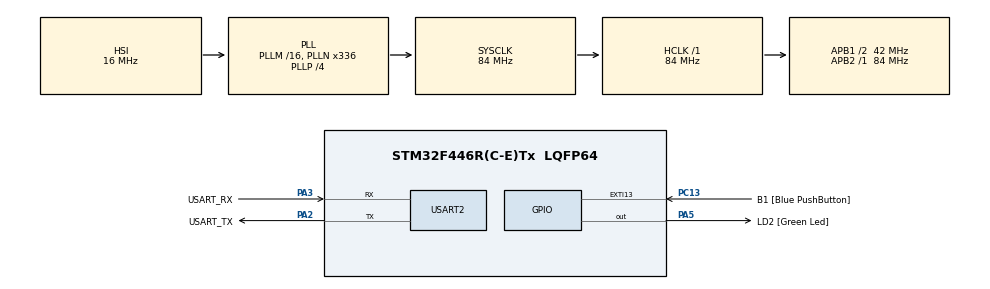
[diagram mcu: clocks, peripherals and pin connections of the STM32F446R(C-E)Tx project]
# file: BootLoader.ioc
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Mcu.Family=STM32F4
Mcu.Name=STM32F446R(C-E)Tx
Mcu.Package=LQFP64
NVIC.PriorityGroup=NVIC_PRIORITYGROUP_0
PA13.GPIO_Label=TMS
PA13.Mode=Serial_Wire
PA13.Signal=SYS_JTMS-SWDIO
PA14.GPIO_Label=TCK
PA14.Mode=Serial_Wire
PA14.Signal=SYS_JTCK-SWCLK
PA2.GPIO_Label=USART_TX
PA2.Mode=Asynchronous
PA2.Signal=USART2_TX
PA3.GPIO_Label=USART_RX
PA3.Mode=Asynchronous
PA3.Signal=USART2_RX
PA5.GPIO_Label=LD2 [Green Led]
PA5.Signal=GPIO_Output
PB3.GPIO_Label=SWO
PB3.Signal=SYS_JTDO-SWO
PC13.GPIO_Label=B1 [Blue PushButton]
PC13.GPIO_ModeDefaultEXTI=GPIO_MODE_IT_FALLING
PC13.Signal=GPXTI13
PC14-OSC32_IN.Mode=LSE-External-Oscillator
PC14-OSC32_IN.Signal=RCC_OSC32_IN
PC15-OSC32_OUT.Mode=LSE-External-Oscillator
PC15-OSC32_OUT.Signal=RCC_OSC32_OUT
PH0-OSC_IN.Mode=HSE-External-Oscillator
PH0-OSC_IN.Signal=RCC_OSC_IN
PH1-OSC_OUT.Mode=HSE-External-Oscillator
PH1-OSC_OUT.Signal=RCC_OSC_OUT
ProjectManager.HeapSize=0x200
ProjectManager.StackSize=0x400
ProjectManager.TargetToolchain=STM32CubeIDE
RCC.48MHZClocksFreq_Value=84000000
RCC.AHBFreq_Value=84000000
RCC.APB1CLKDivider=RCC_HCLK_DIV2
RCC.APB1Freq_Value=42000000
RCC.APB1TimFreq_Value=84000000
RCC.APB2Freq_Value=84000000
RCC.APB2TimFreq_Value=84000000
RCC.CortexFreq_Value=84000000
RCC.FLatency-AdvancedSettings=FLASH_LATENCY_2
RCC.HCLKFreq_Value=84000000
RCC.HSE_VALUE=8000000
RCC.HSI_VALUE=16000000
RCC.PLLN=336
RCC.PLLP=RCC_PLLP_DIV4
RCC.SYSCLKFreq_VALUE=84000000
RCC.SYSCLKSource=RCC_SYSCLKSOURCE_PLLCLK
RCC.USBFreq_Value=168000000
RCC.VCOOutputFreq_Value=336000000
USART2.VirtualMode=VM_ASYNC
board=NUCLEO-F446RE

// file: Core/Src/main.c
/* USER CODE BEGIN Header */
/**
 ******************************************************************************
 * @file           : main.c
 * @brief          : Simple Bootloader example
 ******************************************************************************
 */
/* USER CODE END Header */
#include "main.h"

/* USER CODE BEGIN Includes */
#include "general.h"
#include "stdbool.h"
/* USER CODE END Includes */

UART_HandleTypeDef huart2;

void SystemClock_Config(void);
static void MX_GPIO_Init(void);
static void MX_USART2_UART_Init(void);

/* USER CODE BEGIN 0 */
typedef void (*pFunction)(void);
void goto_APP(void);
pFunction JumpToApplication;
uint32_t JumpAddress;

#define APP_ADD     0x08008000
#define APP_ADDRESS 0x08008000
#define FLASH_PAGE_SIZE 0x4000  // 16 KB typical for STM32F4
#define MAX_APP_SIZE 0x60000    // Example max size (384 KB)

uint8_t rx_buffer[256];

/* USER CODE END 0 */

int main(void)
{

  HAL_Init();
  SystemClock_Config();
  MX_GPIO_Init();
  MX_USART2_UART_Init();

  /* USER CODE BEGIN 2 */

  receive_and_flash();

  goto_APP();

  /* USER CODE END 2 */

  while (1)
  {
    /* USER CODE BEGIN 3 */
    // Optional: put error handling or standby here
    /* USER CODE END 3 */
  }
}

void SystemClock_Config(void) {
	RCC_OscInitTypeDef RCC_OscInitStruct = { 0 };
	RCC_ClkInitTypeDef RCC_ClkInitStruct = { 0 };

	/** Configure the main internal regulator output voltage
	 */
	__HAL_RCC_PWR_CLK_ENABLE();
	__HAL_PWR_VOLTAGESCALING_CONFIG(PWR_REGULATOR_VOLTAGE_SCALE3);

	/** Initializes the RCC Oscillators according to the specified parameters
	 * in the RCC_OscInitTypeDef structure.
	 */
	RCC_OscInitStruct.OscillatorType = RCC_OSCILLATORTYPE_HSI;
	RCC_OscInitStruct.HSIState = RCC_HSI_ON;
	RCC_OscInitStruct.HSICalibrationValue = RCC_HSICALIBRATION_DEFAULT;
	RCC_OscInitStruct.PLL.PLLState = RCC_PLL_ON;
	RCC_OscInitStruct.PLL.PLLSource = RCC_PLLSOURCE_HSI;
	RCC_OscInitStruct.PLL.PLLM = 16;
	RCC_OscInitStruct.PLL.PLLN = 336;
	RCC_OscInitStruct.PLL.PLLP = RCC_PLLP_DIV4;
	RCC_OscInitStruct.PLL.PLLQ = 2;
	RCC_OscInitStruct.PLL.PLLR = 2;
	if (HAL_RCC_OscConfig(&RCC_OscInitStruct) != HAL_OK) {
		Error_Handler();
	}

	/** Initializes the CPU, AHB and APB buses clocks
	 */
	RCC_ClkInitStruct.ClockType = RCC_CLOCKTYPE_HCLK | RCC_CLOCKTYPE_SYSCLK
			| RCC_CLOCKTYPE_PCLK1 | RCC_CLOCKTYPE_PCLK2;
	RCC_ClkInitStruct.SYSCLKSource = RCC_SYSCLKSOURCE_PLLCLK;
	RCC_ClkInitStruct.AHBCLKDivider = RCC_SYSCLK_DIV1;
	RCC_ClkInitStruct.APB1CLKDivider = RCC_HCLK_DIV2;
	RCC_ClkInitStruct.APB2CLKDivider = RCC_HCLK_DIV1;

	if (HAL_RCC_ClockConfig(&RCC_ClkInitStruct, FLASH_LATENCY_2) != HAL_OK) {
		Error_Handler();
	}
}

static void MX_USART2_UART_Init(void) {

	huart2.Instance = USART2;
	huart2.Init.BaudRate = 115200;
	huart2.Init.WordLength = UART_WORDLENGTH_8B;
	huart2.Init.StopBits = UART_STOPBITS_1;
	huart2.Init.Parity = UART_PARITY_NONE;
	huart2.Init.Mode = UART_MODE_TX_RX;
	huart2.Init.HwFlowCtl = UART_HWCONTROL_NONE;
	huart2.Init.OverSampling = UART_OVERSAMPLING_16;
	if (HAL_UART_Init(&huart2) != HAL_OK) {
		Error_Handler();
	}

}

static void MX_GPIO_Init(void) {
	GPIO_InitTypeDef GPIO_InitStruct = { 0 };

	/* GPIO Ports Clock Enable */
	__HAL_RCC_GPIOC_CLK_ENABLE();
	__HAL_RCC_GPIOH_CLK_ENABLE();
	__HAL_RCC_GPIOA_CLK_ENABLE();
	__HAL_RCC_GPIOB_CLK_ENABLE();

	/*Configure GPIO pin Output Level */
	HAL_GPIO_WritePin(LD2_GPIO_Port, LD2_Pin, GPIO_PIN_RESET);

	/*Configure GPIO pin : B1_Pin */
	GPIO_InitStruct.Pin = B1_Pin;
	GPIO_InitStruct.Mode = GPIO_MODE_IT_FALLING;
	GPIO_InitStruct.Pull = GPIO_NOPULL;
	HAL_GPIO_Init(B1_GPIO_Port, &GPIO_InitStruct);

	/*Configure GPIO pin : LD2_Pin */
	GPIO_InitStruct.Pin = LD2_Pin;
	GPIO_InitStruct.Mode = GPIO_MODE_OUTPUT_PP;
	GPIO_InitStruct.Pull = GPIO_NOPULL;
	GPIO_InitStruct.Speed = GPIO_SPEED_FREQ_LOW;
	HAL_GPIO_Init(LD2_GPIO_Port, &GPIO_InitStruct);

	/* USART1 RX (PB7) */
	GPIO_InitStruct.Pin = GPIO_PIN_7;
	GPIO_InitStruct.Mode = GPIO_MODE_AF_PP;
	GPIO_InitStruct.Pull = GPIO_NOPULL;
	GPIO_InitStruct.Speed = GPIO_SPEED_FREQ_VERY_HIGH;
	GPIO_InitStruct.Alternate = GPIO_AF7_USART1;
	HAL_GPIO_Init(GPIOB, &GPIO_InitStruct);
}

/* USER CODE BEGIN 4 */
void goto_APP(void) {
    printf("Bootloader: jumping to app\n");

    // Disable interrupt sources
    HAL_NVIC_DisableIRQ(USART2_IRQn);
    HAL_NVIC_DisableIRQ(EXTI15_10_IRQn);

    // De-init peripherals
    HAL_UART_DeInit(&huart2);
    HAL_RCC_DeInit();

    // Optionally reset GPIOs
    HAL_GPIO_DeInit(GPIOA, GPIO_PIN_All);
    HAL_GPIO_DeInit(GPIOB, GPIO_PIN_All);

    // Set vector table offset (optional)
    SCB->VTOR = APP_ADD;

    // Set MSP
    __set_MSP(*(__IO uint32_t*)APP_ADD);

    // Get reset handler address
    JumpAddress = *(__IO uint32_t*) (APP_ADD + 4);
    JumpToApplication = (pFunction)JumpAddress;

    // Jump
    JumpToApplication();
}

#define EXPECTED_SIZE 100000  // total bytes expected

void receive_and_flash(void)
{
    HAL_StatusTypeDef status;

    // ================================
    // >>> Configure USART1 GPIO pins
    // ================================
    GPIO_InitTypeDef GPIO_InitStruct = {0};

    __HAL_RCC_GPIOB_CLK_ENABLE();
    __HAL_RCC_USART1_CLK_ENABLE();

    // PB6 = USART1_TX
    GPIO_InitStruct.Pin = GPIO_PIN_6;
    GPIO_InitStruct.Mode = GPIO_MODE_AF_PP;
    GPIO_InitStruct.Pull = GPIO_NOPULL;
    GPIO_InitStruct.Speed = GPIO_SPEED_FREQ_VERY_HIGH;
    GPIO_InitStruct.Alternate = GPIO_AF7_USART1;
    HAL_GPIO_Init(GPIOB, &GPIO_InitStruct);

    // PB7 = USART1_RX
    GPIO_InitStruct.Pin = GPIO_PIN_7;
    GPIO_InitStruct.Mode = GPIO_MODE_AF_PP;
    GPIO_InitStruct.Pull = GPIO_NOPULL;
    GPIO_InitStruct.Speed = GPIO_SPEED_FREQ_VERY_HIGH;
    GPIO_InitStruct.Alternate = GPIO_AF7_USART1;
    HAL_GPIO_Init(GPIOB, &GPIO_InitStruct);

    // ===========================
    // >>> Init USART1
    // ===========================
    UART_HandleTypeDef huart1;
    huart1.Instance = USART1;
    huart1.Init.BaudRate = 115200;
    huart1.Init.WordLength = UART_WORDLENGTH_8B;
    huart1.Init.StopBits = UART_STOPBITS_1;
    huart1.Init.Parity = UART_PARITY_NONE;
    huart1.Init.Mode = UART_MODE_TX_RX;
    huart1.Init.HwFlowCtl = UART_HWCONTROL_NONE;
    huart1.Init.OverSampling = UART_OVERSAMPLING_16;
    if (HAL_UART_Init(&huart1) != HAL_OK)
    {
        Error_Handler();
    }

    // Buffer to accumulate received data
    uint8_t *rx_buffer = malloc(EXPECTED_SIZE);
    if (!rx_buffer) {
        // Allocation failed
        Error_Handler();
    }

    uint32_t receivedSize = 0;
    uint32_t startTick = HAL_GetTick();
    const uint32_t timeoutMs = 10000; // 10 seconds overall timeout

    while ((HAL_GetTick() - startTick) < timeoutMs && receivedSize < EXPECTED_SIZE)
    {
        // Receive in small chunks (e.g. 64 bytes) to avoid big blocking
        uint32_t chunkSize = 64;
        if ((EXPECTED_SIZE - receivedSize) < chunkSize) {
            chunkSize = EXPECTED_SIZE - receivedSize;
        }

        status = HAL_UART_Receive(&huart1, rx_buffer + receivedSize, chunkSize, 500);

        if (status == HAL_OK)
        {
            receivedSize += chunkSize;
            startTick = HAL_GetTick();  // reset timeout on receive
        }
        else if (status == HAL_TIMEOUT)
        {
            // no data for 500ms chunk, continue to wait if total time not exceeded
            continue;
        }
        else
        {
            // other errors, break early
            break;
        }
    }

    if (receivedSize > 1000 )
    {
        // We have full data - flash it!

        HAL_FLASH_Unlock();

        FLASH_EraseInitTypeDef EraseInitStruct;
        uint32_t SectorError = 0;
        EraseInitStruct.TypeErase = FLASH_TYPEERASE_SECTORS;
        EraseInitStruct.VoltageRange = FLASH_VOLTAGE_RANGE_3;
        EraseInitStruct.Sector = FLASH_SECTOR_2;
        EraseInitStruct.NbSectors = 6;
        if (HAL_FLASHEx_Erase(&EraseInitStruct, &SectorError) != HAL_OK)
        {
            free(rx_buffer);
            Error_Handler();
        }

        uint32_t appAddress = APP_ADD;

        // Flash in 4-byte words
        for (uint32_t i = 0; i < receivedSize; i += 4)
        {
            uint32_t word = *(uint32_t *)(rx_buffer + i);
            if (HAL_FLASH_Program(FLASH_TYPEPROGRAM_WORD, appAddress, word) != HAL_OK)
            {
                free(rx_buffer);
                Error_Handler();
            }
            appAddress += 4;
        }

        HAL_FLASH_Lock();

        // Print success message
        const char *msg = "Flashing done\r\n";
        HAL_UART_Transmit(&huart2, (uint8_t *)msg, strlen(msg), HAL_MAX_DELAY);
    }
    else
    {
        // Did not receive full data within timeout
        const char *msg = "No data or incomplete\r\n";
        HAL_UART_Transmit(&huart2, (uint8_t *)msg, strlen(msg), HAL_MAX_DELAY);
    }

    free(rx_buffer);

    // ================================
    // >>> Deinit USART1, free GPIO
    // ================================
    HAL_UART_DeInit(&huart1);
    HAL_GPIO_DeInit(GPIOB, GPIO_PIN_6 | GPIO_PIN_7);
    __HAL_RCC_USART1_CLK_DISABLE();
}

/* USER CODE END 4 */

void Error_Handler(void) {
	__disable_irq();
	while (1) {
	}
}
